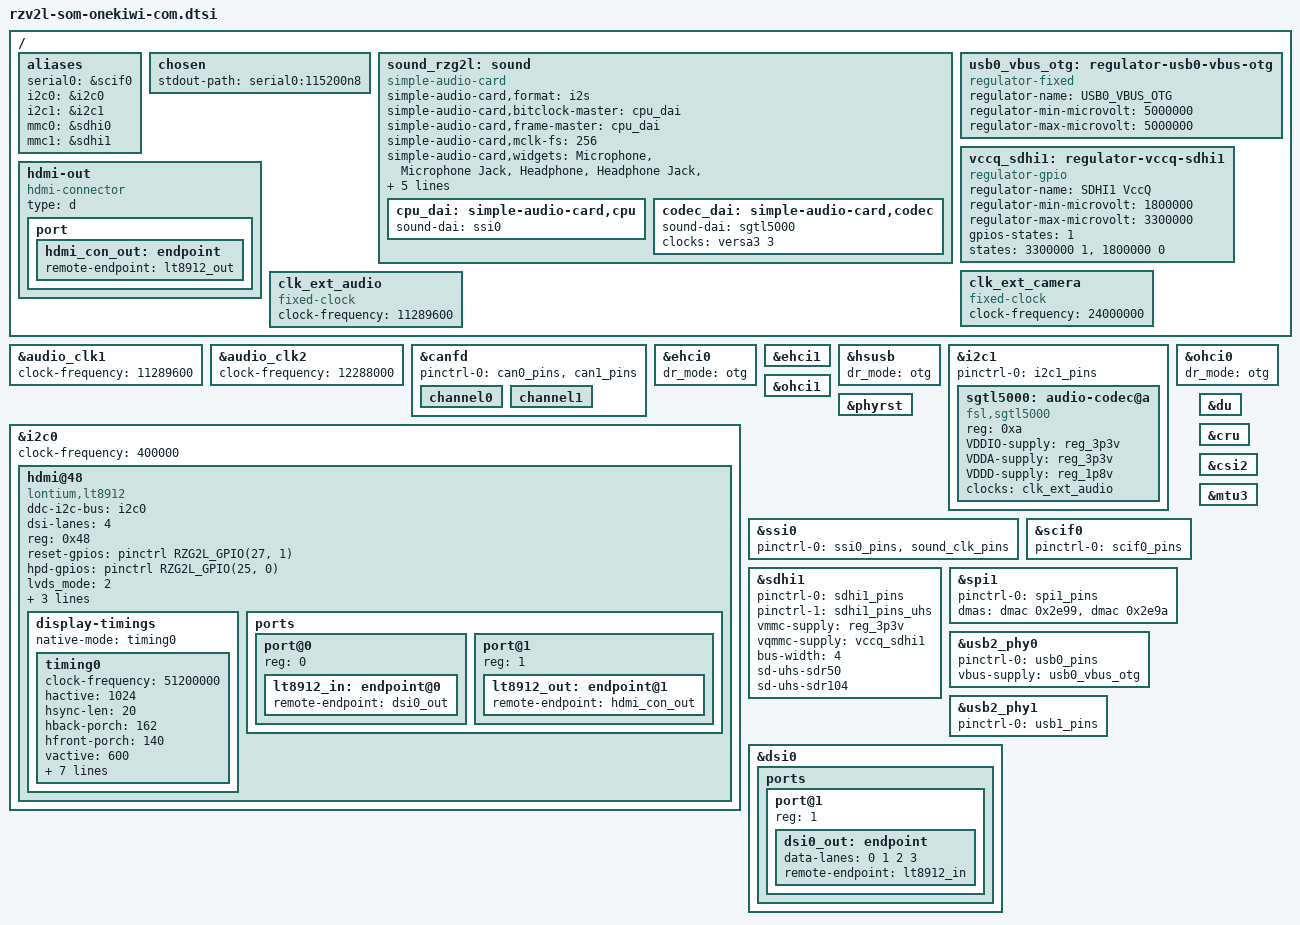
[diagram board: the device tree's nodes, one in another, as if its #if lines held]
// SPDX-License-Identifier: (GPL-2.0-only OR BSD-2-Clause)
/*
 * Device Tree Source for the RZ/{G2L,G2LC,V2L} SMARC EVK common parts
 *
 * Copyright (C) 2022 Renesas Electronics Corp.
 */

#include <dt-bindings/gpio/gpio.h>
#include <dt-bindings/pinctrl/rzg2l-pinctrl.h>

/*
 * SSI-WM8978
 *
 * This command is required when Playback/Capture
 *
 *	amixer cset name='Left Input Mixer L2 Switch' on
 *	amixer cset name='Right Input Mixer R2 Switch' on
 *	amixer cset name='Headphone Playback Volume' 100
 *	amixer cset name='PCM Volume' 100%
 *	amixer cset name='Input PGA Volume' 25
 *
 */

/ {
	aliases {
		serial0 = &scif0;
		i2c0 = &i2c0;
		i2c1 = &i2c1;
		mmc0 = &sdhi0;
		mmc1 = &sdhi1;
	};

	chosen {
		stdout-path = "serial0:115200n8";
	};

	/*
	snd_rzg2l: sound {
		compatible = "simple-audio-card";
		simple-audio-card,format = "i2s";
		simple-audio-card,bitclock-master = <&cpu_dai>;
		simple-audio-card,frame-master = <&cpu_dai>;
		simple-audio-card,mclk-fs = <256>;

		simple-audio-card,widgets = "Microphone", "Microphone Jack";
		simple-audio-card,routing =
			    "L2", "Mic Bias",
			    "R2", "Mic Bias",
			    "Mic Bias", "Microphone Jack";

		cpu_dai: simple-audio-card,cpu {
		};

		codec_dai: simple-audio-card,codec {
			sound-dai = <&wm8978>;
		};
	};*/

	sound_rzg2l: sound {
		compatible = "simple-audio-card";
		simple-audio-card,format = "i2s";
		simple-audio-card,bitclock-master = <&cpu_dai>;
		simple-audio-card,frame-master = <&cpu_dai>;
		simple-audio-card,mclk-fs = <256>;
		simple-audio-card,widgets =
			"Microphone", "Microphone Jack",
			"Headphone", "Headphone Jack",
			"Speaker", "Speaker Ext",
			"Line", "Line In Jack";
		simple-audio-card,routing =
			"MIC_IN", "Microphone Jack",
			"Microphone Jack", "Mic Bias",
			"LINE_IN", "Line In Jack",
			"Headphone Jack", "HP_OUT",
			"Speaker Ext", "LINE_OUT";

		cpu_dai: simple-audio-card,cpu {
			sound-dai = <&ssi0>;
		};
		codec_dai: simple-audio-card,codec {
			sound-dai = <&sgtl5000>;
			clocks = <&versa3 3>;
		};
    };

	usb0_vbus_otg: regulator-usb0-vbus-otg {
		compatible = "regulator-fixed";

		regulator-name = "USB0_VBUS_OTG";
		regulator-min-microvolt = <5000000>;
		regulator-max-microvolt = <5000000>;
	};

	vccq_sdhi1: regulator-vccq-sdhi1 {
		compatible = "regulator-gpio";
		regulator-name = "SDHI1 VccQ";
		regulator-min-microvolt = <1800000>;
		regulator-max-microvolt = <3300000>;
		gpios-states = <1>;
		states = <3300000 1>, <1800000 0>;
	};

	hdmi-out {
		compatible = "hdmi-connector";
		type = "d";

		port {
			hdmi_con_out: endpoint {
				remote-endpoint = <&lt8912_out>;
			};
		};
    };

	clk_ext_camera: clk_ext_camera {
		compatible = "fixed-clock";
		#clock-cells = <0>;
		clock-frequency = <24000000>;
	};

	clk_ext_audio: clk_ext_audio {
		compatible = "fixed-clock";
		#clock-cells = <0>;
		clock-frequency = <11289600>;
	};

	/*
	ov5645_vdddo_1v8: 1p8v {
		compatible = "regulator-fixed";
		regulator-name = "camera_vdddo";
		regulator-min-microvolt = <1800000>;
		regulator-max-microvolt = <1800000>;
		regulator-always-on;
	};

	ov5645_vdda_2v8: 2p8v {
		compatible = "regulator-fixed";
		regulator-name = "camera_vdda";
		regulator-min-microvolt = <2800000>;
		regulator-max-microvolt = <2800000>;
		regulator-always-on;
	};

	ov5645_vddd_1v5: 1p5v {
		compatible = "regulator-fixed";
		regulator-name = "camera_vddd";
		regulator-min-microvolt = <1500000>;
		regulator-max-microvolt = <1500000>;
		regulator-always-on;
	};*/
};

&audio_clk1{
	clock-frequency = <11289600>;
};

&audio_clk2{
	clock-frequency = <12288000>;
};

&canfd {
	pinctrl-0 = <&can0_pins &can1_pins>;
	pinctrl-names = "default";
	status = "okay";

	channel0 {
		status = "okay";
	};

	channel1 {
		status = "okay";
	};
};

&ehci0 {
	dr_mode = "otg";
	status = "okay";
};

&ehci1 {
	status = "okay";
};

&hsusb {
	dr_mode = "otg";
	status = "okay";
};

/*
&i2c0 {
	pinctrl-0 = <&i2c0_pins>;
	pinctrl-names = "default";

	status = "okay";

	ov5645: camera@3c {
		compatible = "ovti,ov5645";
		reg = <0x3c>;
		clock-names = "xclk";
		clocks = <&clk_ext_camera>;
		clock-frequency = <24000000>;
		vdddo-supply = <&ov5645_vdddo_1v8>;
		vdda-supply = <&ov5645_vdda_2v8>;
		vddd-supply = <&ov5645_vddd_1v5>;

		port {
			ov5645_to_csi: endpoint {
				clock-lanes = <0>;
				data-lanes = <1 2>;
				remote-endpoint = <&csi2_in>;
			};
		};
	};
};*/

&i2c0 {
    clock-frequency = <400000>;
    pinctrl-names = "default";
    status = "okay";

	/* MIPI-DSI to HDMI and LVDS adapter */
	hdmi@48 {
		compatible = "lontium,lt8912";
		ddc-i2c-bus = <&i2c0>;
		dsi-lanes = <4>;
		reg = <0x48>;
		reset-gpios = <&pinctrl RZG2L_GPIO(27, 1) GPIO_ACTIVE_HIGH>;
		hpd-gpios = <&pinctrl RZG2L_GPIO(25, 0) GPIO_ACTIVE_HIGH>;
	//	interrupt-parent = <&pinctrl>;
	//	interrupts = <RZG2L_GPIO(2, 0) IRQ_TYPE_EDGE_RISING>;

	/*  LVDS output or HDMI output
		0: lvds
		1: hdmi
		2: hdmi and lvds
    */
		lvds_mode = <2>;
		bit_color = <0> ;    // 0:24bit   1:18bit
		hdmi_mode = <0>;     // 0: 1080P  1:720P
		audio_mode = <2>;     // 0:NONE   1: SPDIF 2: I2S

		display-timings {
			native-mode = <&timing0>;
			timing0:timing0{
					clock-frequency = <51200000>;

					hactive = <1024>;
					hsync-len = <20>;
					hback-porch = <162>;
					hfront-porch = <140>;
					vactive = <600>;
					vsync-len = <3>;
					vback-porch = <20>;
					vfront-porch = <12>;

					vsync-active = <0>;
					hsync-active =<0>;
					de-active =<0>;
					pixelclk-active =<0>;
			};

		};

		ports{
			#address-cells = <1>;
			#size-cells = <0>;
			port@0 {
				reg = <0>;
				lt8912_in: endpoint@0 {
					remote-endpoint = <&dsi0_out>;
				};
			};

			port@1 {
				reg = <1>;
				lt8912_out: endpoint@1 {
					remote-endpoint = <&hdmi_con_out>;
				};
			};
			/*
			port@2 {
				reg = <2>;
				codec_endpoint: endpoint {
						remote-endpoint = <&i2s2_cpu_endpoint>;
				};
             };*/

		};

	};

};


&i2c1 {
	pinctrl-0 = <&i2c1_pins>;
	pinctrl-names = "default";
	status = "okay";

	sgtl5000: audio-codec@a {
		#sound-dai-cells = <0>;
		compatible = "fsl,sgtl5000";
		reg = <0xa>;
		VDDIO-supply = <&reg_3p3v>;
		VDDA-supply = <&reg_3p3v>;
		VDDD-supply = <&reg_1p8v>;
		clocks = <&clk_ext_audio>;
	};

	/*
	adv7535: hdmi@3d {
		compatible = "adi,adv7535";
		reg = <0x3d>;

		avdd-supply = <&reg_1p8v>;
		dvdd-supply = <&reg_1p8v>;
		pvdd-supply = <&reg_1p8v>;
		a2vdd-supply = <&reg_1p8v>;
		v3p3-supply = <&reg_3p3v>;
		v1p2-supply = <&reg_1p8v>;

		adi,dsi-lanes = <4>;

		ports {
			#address-cells = <1>;
			#size-cells = <0>;

			port@0 {
				reg = <0>;
				adv7535_in: endpoint@0 {
					remote-endpoint = <&dsi0_out>;
				};
			};

			port@1 {
				reg = <1>;
				adv7535_out: endpoint@1 {
					remote-endpoint = <&hdmi_con_out>;
				};
			};

			port@2 {
				reg = <2>;
				codec_endpoint: endpoint {
					remote-endpoint = <&i2s2_cpu_endpoint>;
				};
			};
		};
	};*/
};

&ohci0 {
	dr_mode = "otg";
	status = "okay";
};

&ohci1 {
	status = "okay";
};

&phyrst {
	status = "okay";
};

&ssi0 {
	pinctrl-0 = <&ssi0_pins>;
	pinctrl-0 = <&ssi0_pins &sound_clk_pins>;
	pinctrl-names = "default";
	status = "okay";
};

&scif0 {
	pinctrl-0 = <&scif0_pins>;
	pinctrl-names = "default";
	status = "okay";
};

&sdhi1 {
	pinctrl-0 = <&sdhi1_pins>;
	pinctrl-1 = <&sdhi1_pins_uhs>;
	pinctrl-names = "default", "state_uhs";

	vmmc-supply = <&reg_3p3v>;
	vqmmc-supply = <&vccq_sdhi1>;
	bus-width = <4>;
	sd-uhs-sdr50;
	sd-uhs-sdr104;
	status = "okay";
};

#if (!MTU3_PWM_SUPPORT)
&spi1 {
	pinctrl-0 = <&spi1_pins>;
	pinctrl-names = "default";
	dmas = <&dmac 0x2e99>, <&dmac 0x2e9a>;
	dma-names = "tx", "rx";

	status = "okay";
};
#endif

&usb2_phy0 {
	pinctrl-0 = <&usb0_pins>;
	pinctrl-names = "default";

	vbus-supply = <&usb0_vbus_otg>;
	status = "okay";
};

&usb2_phy1 {
	pinctrl-0 = <&usb1_pins>;
	pinctrl-names = "default";

	status = "okay";
};

&du {
	status = "okay";
};

&dsi0 {
	status = "okay";
	
	ports {
		port@1 {
			reg = <1>;
			dsi0_out: endpoint {
				data-lanes = <0 1 2 3>;
				remote-endpoint = <&lt8912_in>;
			};
		};
	};
};

&cru {
	status = "okay";
};

&csi2 {
	status = "okay";

	/*
	ports {
		port {
			csi2_in: endpoint {
				clock-lanes = <0>;
				data-lanes = <1 2>;
				remote-endpoint = <&ov5645_to_csi>;
			};
		};
	};*/
};

&mtu3 {
	status = "okay";
};
